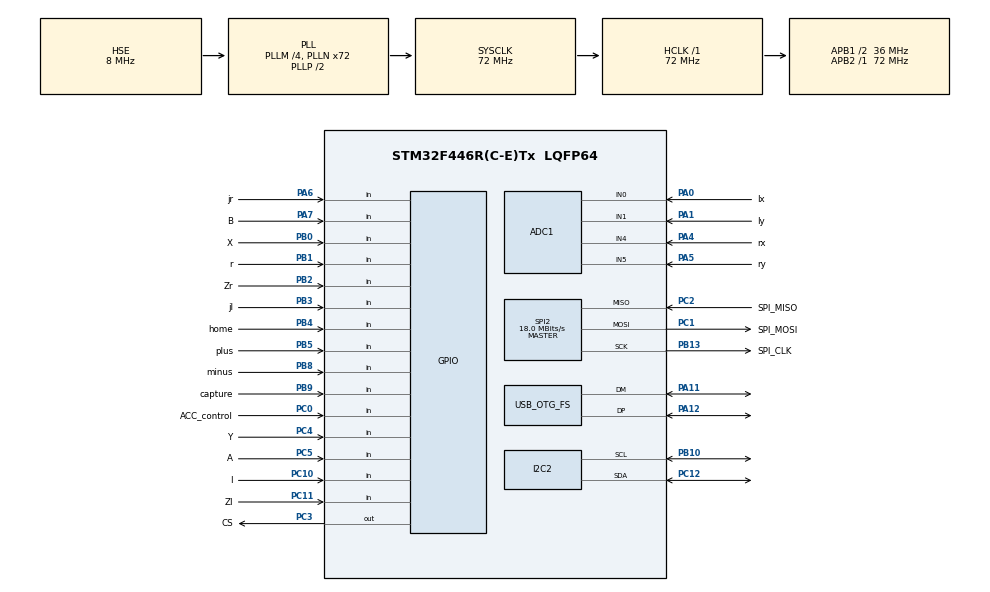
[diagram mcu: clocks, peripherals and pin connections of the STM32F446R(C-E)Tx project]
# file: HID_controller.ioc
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ADC1.Channel-0\#ChannelRegularConversion=ADC_CHANNEL_0
ADC1.Channel-1\#ChannelRegularConversion=ADC_CHANNEL_1
ADC1.Channel-2\#ChannelRegularConversion=ADC_CHANNEL_4
ADC1.Channel-3\#ChannelRegularConversion=ADC_CHANNEL_5
ADC1.ContinuousConvMode=DISABLE
ADC1.DMAContinuousRequests=ENABLE
ADC1.EOCSelection=ADC_EOC_SEQ_CONV
ADC1.ExternalTrigConv=ADC_EXTERNALTRIGCONV_T3_TRGO
ADC1.NbrOfConversion=4
ADC1.NbrOfConversionFlag=1
ADC1.Rank-0\#ChannelRegularConversion=1
ADC1.Rank-1\#ChannelRegularConversion=2
ADC1.Rank-2\#ChannelRegularConversion=3
ADC1.Rank-3\#ChannelRegularConversion=4
ADC1.SamplingTime-0\#ChannelRegularConversion=ADC_SAMPLETIME_480CYCLES
ADC1.SamplingTime-1\#ChannelRegularConversion=ADC_SAMPLETIME_480CYCLES
ADC1.SamplingTime-2\#ChannelRegularConversion=ADC_SAMPLETIME_480CYCLES
ADC1.SamplingTime-3\#ChannelRegularConversion=ADC_SAMPLETIME_480CYCLES
ADC1.master=1
Dma.ADC1.0.Direction=DMA_PERIPH_TO_MEMORY
Dma.ADC1.0.FIFOMode=DMA_FIFOMODE_DISABLE
Dma.ADC1.0.Instance=DMA2_Stream0
Dma.ADC1.0.MemDataAlignment=DMA_MDATAALIGN_HALFWORD
Dma.ADC1.0.MemInc=DMA_MINC_ENABLE
Dma.ADC1.0.Mode=DMA_CIRCULAR
Dma.ADC1.0.PeriphDataAlignment=DMA_PDATAALIGN_HALFWORD
Dma.ADC1.0.PeriphInc=DMA_PINC_DISABLE
Dma.ADC1.0.Priority=DMA_PRIORITY_HIGH
Dma.Request0=ADC1
Mcu.Family=STM32F4
Mcu.Name=STM32F446R(C-E)Tx
Mcu.Package=LQFP64
NVIC.ADC_IRQn=true\:0\:0\:false\:false\:true\:true\:true\:true
NVIC.DMA2_Stream0_IRQn=true\:0\:0\:false\:false\:true\:false\:true\:true
NVIC.OTG_FS_IRQn=true\:0\:0\:false\:false\:true\:true\:true\:true
NVIC.PriorityGroup=NVIC_PRIORITYGROUP_4
PA0-WKUP.GPIO_Label=lx
PA0-WKUP.Signal=ADCx_IN0
PA1.GPIO_Label=ly
PA1.Signal=ADCx_IN1
PA11.Mode=Device_Only
PA11.Signal=USB_OTG_FS_DM
PA12.Mode=Device_Only
PA12.Signal=USB_OTG_FS_DP
PA13.Mode=Serial_Wire
PA13.Signal=SYS_JTMS-SWDIO
PA14.Mode=Serial_Wire
PA14.Signal=SYS_JTCK-SWCLK
PA4.GPIO_Label=rx
PA4.Signal=ADCx_IN4
PA5.GPIO_Label=ry
PA5.Signal=ADCx_IN5
PA6.GPIO_Label=jr
PA6.GPIO_Mode=GPIO_MODE_INPUT
PA6.GPIO_PuPd=GPIO_PULLUP
PA6.Signal=GPIO_Input
PA7.GPIO_Label=B
PA7.GPIO_Mode=GPIO_MODE_INPUT
PA7.GPIO_PuPd=GPIO_PULLUP
PA7.Signal=GPIO_Input
PB0.GPIO_Label=X
PB0.GPIO_Mode=GPIO_MODE_INPUT
PB0.GPIO_PuPd=GPIO_PULLUP
PB0.Signal=GPIO_Input
PB1.GPIO_Label=r
PB1.GPIO_Mode=GPIO_MODE_INPUT
PB1.GPIO_PuPd=GPIO_PULLUP
PB1.Signal=GPIO_Input
PB10.Mode=I2C
PB10.Signal=I2C2_SCL
PB13.GPIO_Label=SPI_CLK
PB13.Mode=Full_Duplex_Master
PB13.Signal=SPI2_SCK
PB2.GPIO_Label=Zr
PB2.GPIO_Mode=GPIO_MODE_INPUT
PB2.GPIO_PuPd=GPIO_PULLUP
PB2.Signal=GPIO_Input
PB3.GPIO_Label=jl
PB3.GPIO_PuPd=GPIO_PULLUP
PB3.Signal=GPIO_Input
PB4.GPIO_Label=home
PB4.GPIO_PuPd=GPIO_PULLUP
PB4.Signal=GPIO_Input
PB5.GPIO_Label=plus
PB5.GPIO_PuPd=GPIO_PULLUP
PB5.Signal=GPIO_Input
PB8.GPIO_Label=minus
PB8.GPIO_PuPd=GPIO_PULLUP
PB8.Signal=GPIO_Input
PB9.GPIO_Label=capture
PB9.GPIO_PuPd=GPIO_PULLUP
PB9.Signal=GPIO_Input
PC0.GPIO_Label=ACC_control
PC0.GPIO_PuPd=GPIO_PULLUP
PC0.Signal=GPIO_Input
PC1.GPIO_Label=SPI_MOSI
PC1.Mode=Full_Duplex_Master
PC1.Signal=SPI2_MOSI
PC10.GPIO_Label=l
PC10.GPIO_Mode=GPIO_MODE_INPUT
PC10.GPIO_PuPd=GPIO_PULLUP
PC10.Signal=GPIO_Input
PC11.GPIO_Label=Zl
PC11.GPIO_Mode=GPIO_MODE_INPUT
PC11.GPIO_PuPd=GPIO_PULLUP
PC11.Signal=GPIO_Input
PC12.Mode=I2C
PC12.Signal=I2C2_SDA
PC2.GPIO_Label=SPI_MISO
PC2.Mode=Full_Duplex_Master
PC2.Signal=SPI2_MISO
PC3.GPIO_Label=CS
PC3.GPIO_PuPd=GPIO_PULLUP
PC3.PinState=GPIO_PIN_SET
PC3.Signal=GPIO_Output
PC4.GPIO_Label=Y
PC4.GPIO_PuPd=GPIO_PULLUP
PC4.Signal=GPIO_Input
PC5.GPIO_Label=A
PC5.GPIO_Mode=GPIO_MODE_INPUT
PC5.GPIO_PuPd=GPIO_PULLUP
PC5.Signal=GPIO_Input
PH0-OSC_IN.Mode=HSE-External-Clock-Source
PH0-OSC_IN.Signal=RCC_OSC_IN
PH1-OSC_OUT.Mode=HSE-External-Clock-Source
PH1-OSC_OUT.Signal=RCC_OSC_OUT
ProjectManager.HeapSize=0x200
ProjectManager.StackSize=0x400
ProjectManager.TargetToolchain=STM32CubeIDE
RCC.AHBFreq_Value=72000000
RCC.APB1CLKDivider=RCC_HCLK_DIV2
RCC.APB1Freq_Value=36000000
RCC.APB1TimFreq_Value=72000000
RCC.APB2Freq_Value=72000000
RCC.APB2TimFreq_Value=72000000
RCC.CortexFreq_Value=72000000
RCC.HCLKFreq_Value=72000000
RCC.HSE_VALUE=8000000
RCC.PLLM=4
RCC.PLLN=72
RCC.PLLQ=3
RCC.SYSCLKFreq_VALUE=72000000
RCC.SYSCLKSource=RCC_SYSCLKSOURCE_PLLCLK
RCC.USBFreq_Value=48000000
RCC.VCOOutputFreq_Value=144000000
SH.ADCx_IN0.0=ADC1_IN0,IN0
SH.ADCx_IN1.0=ADC1_IN1,IN1
SH.ADCx_IN4.0=ADC1_IN4,IN4
SH.ADCx_IN5.0=ADC1_IN5,IN5
SPI2.CLKPhase=SPI_PHASE_2EDGE
SPI2.CLKPolarity=SPI_POLARITY_HIGH
SPI2.CalculateBaudRate=18.0 MBits/s
SPI2.Direction=SPI_DIRECTION_2LINES
SPI2.Mode=SPI_MODE_MASTER
SPI2.VirtualType=VM_MASTER
TIM3.Period=100-1
TIM3.Prescaler=2600-1
TIM3.TIM_MasterOutputTrigger=TIM_TRGO_UPDATE
USB_DEVICE.CLASS_NAME_FS=CUSTOM_HID
USB_DEVICE.USBD_CUSTOM_HID_REPORT_DESC_SIZE-CUSTOM_HID_FS=56
USB_DEVICE.USBD_CUSTOMHID_OUTREPORT_BUF_SIZE-CUSTOM_HID_FS=64
USB_DEVICE.USBD_LPM_ENABLED=0
USB_DEVICE.USBD_SELF_POWERED=0
USB_DEVICE.VirtualMode-CUSTOM_HID_FS=CustomHid
USB_DEVICE.VirtualModeFS=Custom_Hid_FS
USB_OTG_FS.VirtualMode=Device_Only
VP_TIM3_VS_ClockSourceINT.Mode=Internal
VP_USB_DEVICE_VS_USB_DEVICE_CUSTOM_HID_FS.Mode=CUSTOM_HID_FS
board=custom

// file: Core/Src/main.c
/* USER CODE BEGIN Header */
/**
  ******************************************************************************
  * @file           : main.c
  * @brief          : Main program body
  ******************************************************************************
  * @attention
  *
  * Copyright (c) 2025 STMicroelectronics.
  * All rights reserved.
  *
  * This software is licensed under terms that can be found in the LICENSE file
  * in the root directory of this software component.
  * If no LICENSE file comes with this software, it is provided AS-IS.
  *
  ******************************************************************************
  */

/* USER CODE END Header */
#include "main.h"
#include "adc.h"
#include "dma.h"
#include "i2c.h"
#include "spi.h"
#include "tim.h"
#include "usb_device.h"
#include "gpio.h"

/* USER CODE BEGIN Includes */
#include "main_loop.h"
#include "joystick.h"
#include "mpu.h"

/* USER CODE END Includes */

void SystemClock_Config(void);

int main(void)
{

  /* MCU Configuration--------------------------------------------------------*/

  /* Reset of all peripherals, Initializes the Flash interface and the Systick. */
  HAL_Init();

  /* Configure the system clock */
  SystemClock_Config();

  /* Initialize all configured peripherals */
  MX_GPIO_Init();
  MX_DMA_Init();
  MX_ADC1_Init();
  MX_TIM3_Init();
  MX_USB_DEVICE_Init();
  MX_SPI2_Init();
  MX_I2C2_Init();
  /* USER CODE BEGIN 2 */
  joystick_start_scan();
  //mpu_init();
  mpu_init_gyro();
  /* USER CODE END 2 */

  /* Infinite loop */
  /* USER CODE BEGIN WHILE */
  while (1)
  {
	main_loop();
    /* USER CODE END WHILE */

  }
}

void SystemClock_Config(void)
{
  RCC_OscInitTypeDef RCC_OscInitStruct = {0};
  RCC_ClkInitTypeDef RCC_ClkInitStruct = {0};

  /** Configure the main internal regulator output voltage
  */
  __HAL_RCC_PWR_CLK_ENABLE();
  __HAL_PWR_VOLTAGESCALING_CONFIG(PWR_REGULATOR_VOLTAGE_SCALE3);

  /** Initializes the RCC Oscillators according to the specified parameters
  * in the RCC_OscInitTypeDef structure.
  */
  RCC_OscInitStruct.OscillatorType = RCC_OSCILLATORTYPE_HSE;
  RCC_OscInitStruct.HSEState = RCC_HSE_BYPASS;
  RCC_OscInitStruct.PLL.PLLState = RCC_PLL_ON;
  RCC_OscInitStruct.PLL.PLLSource = RCC_PLLSOURCE_HSE;
  RCC_OscInitStruct.PLL.PLLM = 4;
  RCC_OscInitStruct.PLL.PLLN = 72;
  RCC_OscInitStruct.PLL.PLLP = RCC_PLLP_DIV2;
  RCC_OscInitStruct.PLL.PLLQ = 3;
  RCC_OscInitStruct.PLL.PLLR = 2;
  if (HAL_RCC_OscConfig(&RCC_OscInitStruct) != HAL_OK)
  {
    Error_Handler();
  }

  /** Initializes the CPU, AHB and APB buses clocks
  */
  RCC_ClkInitStruct.ClockType = RCC_CLOCKTYPE_HCLK|RCC_CLOCKTYPE_SYSCLK
                              |RCC_CLOCKTYPE_PCLK1|RCC_CLOCKTYPE_PCLK2;
  RCC_ClkInitStruct.SYSCLKSource = RCC_SYSCLKSOURCE_PLLCLK;
  RCC_ClkInitStruct.AHBCLKDivider = RCC_SYSCLK_DIV1;
  RCC_ClkInitStruct.APB1CLKDivider = RCC_HCLK_DIV2;
  RCC_ClkInitStruct.APB2CLKDivider = RCC_HCLK_DIV1;

  if (HAL_RCC_ClockConfig(&RCC_ClkInitStruct, FLASH_LATENCY_2) != HAL_OK)
  {
    Error_Handler();
  }
}

void Error_Handler(void)
{
  __disable_irq();
  while (1)
  {
  }
}
